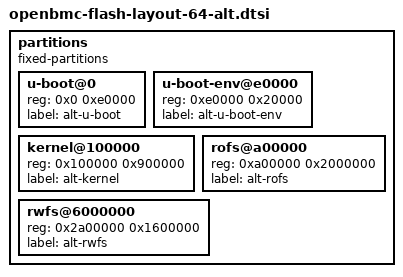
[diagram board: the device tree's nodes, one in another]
partitions {
	compatible = "fixed-partitions";
	#address-cells = <1>;
	#size-cells = <1>;
	u-boot@0 {
		reg = <0x0 0xe0000>;  
		label = "alt-u-boot";
	};
	u-boot-env@e0000 {
		reg = <0xe0000 0x20000>;  
		label = "alt-u-boot-env";
	};
	kernel@100000 {
		reg = <0x100000 0x900000>;  
		label = "alt-kernel";
	};
	rofs@a00000 {
		reg = <0xa00000 0x2000000>;  
		label = "alt-rofs";
	};
	rwfs@6000000 {
		reg = <0x2a00000 0x1600000>;  
		label = "alt-rwfs";
	};
};
